VERSION "HIPBNYYYYYYYYYYYYYYYYYYYYYYYYYYYYYYYYYYYYY/4/%%%/4/'%**4YYY///"

NS_ :

BS_:

BU_:

BO_ 256 Measurement: 8 Vector__XXX
 SG_ Current : 7|32@0- (1.5258789063e-005,0) [0|0] "A" Vector__XXX
 SG_ Voltage : 39|32@0- (1.5258789063e-005,0) [0|0] "V" Vector__XXX

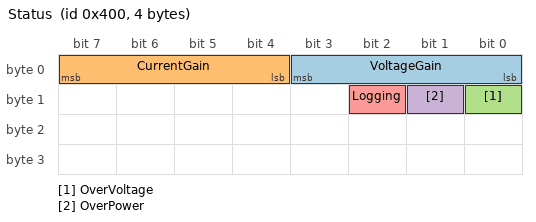
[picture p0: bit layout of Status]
BO_ 1024 Status: 4 Vector__XXX
 SG_ VoltageGain : 3|4@0+ (1,0) [0|0] "bool" Vector__XXX
 SG_ CurrentGain : 7|4@0+ (1,0) [0|0] "" Vector__XXX
 SG_ OverVoltage : 8|1@0+ (1,0) [0|0] "bool" Vector__XXX
 SG_ OverPower : 9|1@0+ (1,0) [0|0] "bool" Vector__XXX
 SG_ Logging : 10|1@0+ (1,0) [0|0] "" Vector__XXX

BO_ 2023 Reserved1: 8 Vector__XXX

BO_ 2031 Reserved2: 8 Vector__XXX/Users/sean/Downloads/NLG5_BRUSA.dbc

CM_ BO_ 2023 "This CAN id is used for communication between the energy meter and the download tool.";
CM_ BO_ 2031 "This CAN id is used for communication between the energy meter and the download tool.";
VAL_ 1024 CurrentGain 0 "x1" 1 "x2" 2 "x4" 3 "x8" 4 "x16" 5 "x32" ;
VAL_ 1024 Logging 0 "x1" 1 "x2" 2 "x4" 3 "x8" 4 "x16" 5 "x32" ;/Users/sean/Downloads/NLG5_BRUSA.dbc
